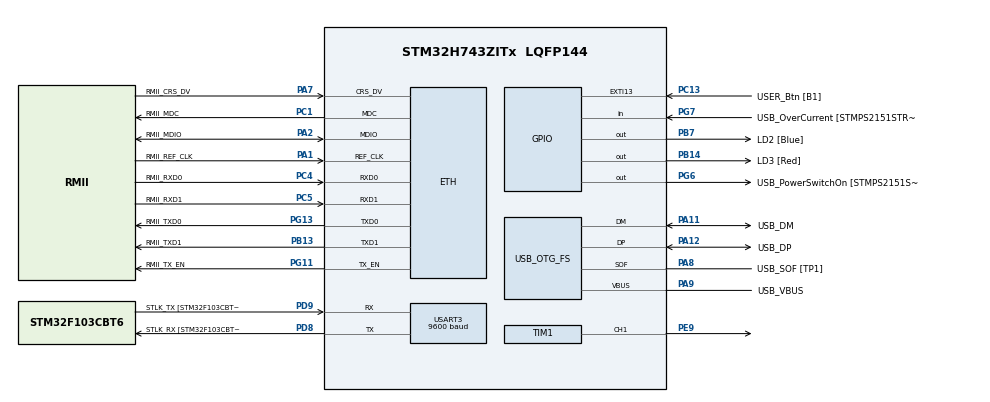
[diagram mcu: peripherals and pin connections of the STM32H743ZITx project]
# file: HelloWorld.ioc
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ETH.MediaInterface=HAL_ETH_RMII_MODE
Mcu.Family=STM32H7
Mcu.Name=STM32H743ZITx
Mcu.Package=LQFP144
NVIC.PriorityGroup=NVIC_PRIORITYGROUP_4
NVIC.USART3_IRQn=true\:0\:0\:false\:false\:true\:true\:true
PA1.GPIO_Label=RMII_REF_CLK
PA1.Mode=RMII
PA1.Signal=ETH_REF_CLK
PA10.GPIO_Label=USB_ID
PA10.Signal=USB_OTG_FS_ID
PA11.GPIO_Label=USB_DM
PA11.Mode=Device_Only
PA11.Signal=USB_OTG_FS_DM
PA12.GPIO_Label=USB_DP
PA12.Mode=Device_Only
PA12.Signal=USB_OTG_FS_DP
PA13\ (JTMS/SWDIO).Mode=Serial_Wire
PA13\ (JTMS/SWDIO).Signal=DEBUG_JTMS-SWDIO
PA14\ (JTCK/SWCLK).Mode=Serial_Wire
PA14\ (JTCK/SWCLK).Signal=DEBUG_JTCK-SWCLK
PA2.GPIO_Label=RMII_MDIO
PA2.Mode=RMII
PA2.Signal=ETH_MDIO
PA7.GPIO_Label=RMII_CRS_DV
PA7.Mode=RMII
PA7.Signal=ETH_CRS_DV
PA8.GPIO_Label=USB_SOF [TP1]
PA8.Mode=Activate_SOF_FS
PA8.Signal=USB_OTG_FS_SOF
PA9.GPIO_Label=USB_VBUS
PA9.Mode=Activate_VBUS
PA9.Signal=USB_OTG_FS_VBUS
PB13.GPIO_Label=RMII_TXD1
PB13.Mode=RMII
PB13.Signal=ETH_TXD1
PB14.GPIO_Label=LD3 [Red]
PB14.Signal=GPIO_Output
PB7.GPIO_Label=LD2 [Blue]
PB7.Signal=GPIO_Output
PC1.GPIO_Label=RMII_MDC
PC1.Mode=RMII
PC1.Signal=ETH_MDC
PC13.GPIO_Label=USER_Btn [B1]
PC13.Signal=GPXTI13
PC14-OSC32_IN\ (OSC32_IN).Mode=LSE-External-Oscillator
PC14-OSC32_IN\ (OSC32_IN).Signal=RCC_OSC32_IN
PC15-OSC32_OUT\ (OSC32_OUT).Mode=LSE-External-Oscillator
PC15-OSC32_OUT\ (OSC32_OUT).Signal=RCC_OSC32_OUT
PC4.GPIO_Label=RMII_RXD0
PC4.Mode=RMII
PC4.Signal=ETH_RXD0
PC5.GPIO_Label=RMII_RXD1
PC5.Mode=RMII
PC5.Signal=ETH_RXD1
PD8.GPIO_Label=STLK_RX [STM32F103CBT6_PA3]
PD8.Mode=Asynchronous
PD8.Signal=USART3_TX
PD9.GPIO_Label=STLK_TX [STM32F103CBT6_PA2]
PD9.Mode=Asynchronous
PD9.Signal=USART3_RX
PE9.Signal=S_TIM1_CH1
PG11.GPIO_Label=RMII_TX_EN
PG11.Mode=RMII
PG11.Signal=ETH_TX_EN
PG13.GPIO_Label=RMII_TXD0
PG13.Mode=RMII
PG13.Signal=ETH_TXD0
PG6.GPIO_Label=USB_PowerSwitchOn [STMPS2151STR_EN]
PG6.Signal=GPIO_Output
PG7.GPIO_Label=USB_OverCurrent [STMPS2151STR_FAULT]
PG7.Signal=GPIO_Input
PH0-OSC_IN\ (PH0).GPIO_Label=MCO
PH0-OSC_IN\ (PH0).Mode=HSE-External-Clock-Source
PH0-OSC_IN\ (PH0).Signal=RCC_OSC_IN
PH1-OSC_OUT\ (PH1).Signal=RCC_OSC_OUT
ProjectManager.HeapSize=0x200
ProjectManager.StackSize=0x400
ProjectManager.TargetToolchain=STM32CubeIDE
RCC.48MHZClocksFreq_Value=24000000
RCC.ADCFreq_Value=16125000
RCC.AHBFreq_Value=216000000
RCC.APB1CLKDivider=RCC_HCLK_DIV4
RCC.APB1Freq_Value=96000000
RCC.APB1TimFreq_Value=108000000
RCC.APB2CLKDivider=RCC_HCLK_DIV2
RCC.APB2Freq_Value=96000000
RCC.APB2TimFreq_Value=216000000
RCC.APB3Freq_Value=96000000
RCC.APB4Freq_Value=96000000
RCC.CortexFreq_Value=96000000
RCC.DIVM1=1
RCC.DIVN1=24
RCC.DIVQ1=4
RCC.HCLKFreq_Value=96000000
RCC.HSE_VALUE=8000000
RCC.HSI_VALUE=64000000
RCC.PLLM=25
RCC.PLLMUL=RCC_PLL_MUL9
RCC.PLLN=432
RCC.PLLQ=9
RCC.PRESCALERUSB=RCC_USBCLKSOURCE_PLL_DIV1_5
RCC.PWR_Regulator_Voltage_Scale=PWR_REGULATOR_VOLTAGE_SCALE1
RCC.SYSCLKFreq_VALUE=96000000
RCC.SYSCLKSource=RCC_SYSCLKSOURCE_PLLCLK
RCC.SYSCLKSourceVirtual=RCC_SYSCLKSOURCE_PLLCLK
RCC.USBFreq_Value=48000000
RCC.VCOOutputFreq_Value=432000000
SH.S_TIM1_CH1.0=TIM1_CH1,PWM Generation1 CH1
TIM1.Channel-PWM\ Generation1\ CH1=TIM_CHANNEL_1
USART3.BaudRate=9600
USART3.FIFOMode=FIFOMODE_ENABLE
USART3.TXFIFOThreshold=TXFIFO_THRESHOLD_1EIGHTHFULL
USART3.VirtualMode-Asynchronous=VM_ASYNC
USB_OTG_FS.VirtualMode=Device_Only
VP_TIM1_VS_ClockSourceINT.Mode=Internal
board=NUCLEO-H743ZI

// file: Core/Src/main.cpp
/* USER CODE BEGIN Header */
/**
  ******************************************************************************
  * @file           : main.c
  * @brief          : Main program body
  ******************************************************************************
  * @attention
  *
  * <h2><center>&copy; Copyright (c) 2020 STMicroelectronics.
  * All rights reserved.</center></h2>
  *
  * This software component is licensed by ST under BSD 3-Clause license,
  * the "License"; You may not use this file except in compliance with the
  * License. You may obtain a copy of the License at:
  *                        opensource.org/licenses/BSD-3-Clause
  *
  ******************************************************************************
  */
/* USER CODE END Header */

#include "main.h"
#include "string.h"

/* USER CODE BEGIN Includes */
#include "applicationManager.h"
/* USER CODE END Includes */

#if defined ( __ICCARM__ ) /*!< IAR Compiler */

#pragma location=0x30040000
ETH_DMADescTypeDef  DMARxDscrTab[ETH_RX_DESC_CNT]; /* Ethernet Rx DMA Descriptors */
#pragma location=0x30040060
ETH_DMADescTypeDef  DMATxDscrTab[ETH_TX_DESC_CNT]; /* Ethernet Tx DMA Descriptors */
#pragma location=0x30040200
uint8_t Rx_Buff[ETH_RX_DESC_CNT][ETH_MAX_PACKET_SIZE]; /* Ethernet Receive Buffers */

#elif defined ( __CC_ARM )  /* MDK ARM Compiler */

__attribute__((at(0x30040000))) ETH_DMADescTypeDef  DMARxDscrTab[ETH_RX_DESC_CNT]; /* Ethernet Rx DMA Descriptors */
__attribute__((at(0x30040060))) ETH_DMADescTypeDef  DMATxDscrTab[ETH_TX_DESC_CNT]; /* Ethernet Tx DMA Descriptors */
__attribute__((at(0x30040200))) uint8_t Rx_Buff[ETH_RX_DESC_CNT][ETH_MAX_PACKET_SIZE]; /* Ethernet Receive Buffer */

#elif defined ( __GNUC__ ) /* GNU Compiler */

ETH_DMADescTypeDef DMARxDscrTab[ETH_RX_DESC_CNT] __attribute__((section(".RxDecripSection"))); /* Ethernet Rx DMA Descriptors */
ETH_DMADescTypeDef DMATxDscrTab[ETH_TX_DESC_CNT] __attribute__((section(".TxDecripSection")));   /* Ethernet Tx DMA Descriptors */
uint8_t Rx_Buff[ETH_RX_DESC_CNT][ETH_MAX_PACKET_SIZE] __attribute__((section(".RxArraySection"))); /* Ethernet Receive Buffers */

#endif

ETH_TxPacketConfig TxConfig;

ETH_HandleTypeDef heth;

TIM_HandleTypeDef htim1;

UART_HandleTypeDef huart3;

PCD_HandleTypeDef hpcd_USB_OTG_FS;

/* USER CODE BEGIN PV */
ApplicationManager appMgr;
/* USER CODE END PV */

void SystemClock_Config(void);
static void MX_GPIO_Init(void);
static void MX_ETH_Init(void);
static void MX_USART3_UART_Init(void);
static void MX_USB_OTG_FS_PCD_Init(void);
static void MX_TIM1_Init(void);

int main(void)
{

  /* MCU Configuration--------------------------------------------------------*/

  /* Reset of all peripherals, Initializes the Flash interface and the Systick. */
  HAL_Init();

  /* Configure the system clock */
  SystemClock_Config();

  /* Initialize all configured peripherals */
  MX_GPIO_Init();
  MX_ETH_Init();
  MX_USART3_UART_Init();
  MX_USB_OTG_FS_PCD_Init();
  MX_TIM1_Init();
  /* USER CODE BEGIN 2 */
  appMgr.init(&huart3);
  /* USER CODE END 2 */

  /* Infinite loop */
  while (1)
  {
	  appMgr.executeMainFunction();
  }
}

void SystemClock_Config(void)
{
  RCC_OscInitTypeDef RCC_OscInitStruct = {0};
  RCC_ClkInitTypeDef RCC_ClkInitStruct = {0};
  RCC_PeriphCLKInitTypeDef PeriphClkInitStruct = {0};

  /** Supply configuration update enable
  */
  HAL_PWREx_ConfigSupply(PWR_LDO_SUPPLY);
  /** Configure the main internal regulator output voltage
  */
  __HAL_PWR_VOLTAGESCALING_CONFIG(PWR_REGULATOR_VOLTAGE_SCALE1);

  while(!__HAL_PWR_GET_FLAG(PWR_FLAG_VOSRDY)) {}
  /** Initializes the CPU, AHB and APB busses clocks
  */
  RCC_OscInitStruct.OscillatorType = RCC_OSCILLATORTYPE_HSE;
  RCC_OscInitStruct.HSEState = RCC_HSE_BYPASS;
  RCC_OscInitStruct.PLL.PLLState = RCC_PLL_ON;
  RCC_OscInitStruct.PLL.PLLSource = RCC_PLLSOURCE_HSE;
  RCC_OscInitStruct.PLL.PLLM = 1;
  RCC_OscInitStruct.PLL.PLLN = 24;
  RCC_OscInitStruct.PLL.PLLP = 2;
  RCC_OscInitStruct.PLL.PLLQ = 4;
  RCC_OscInitStruct.PLL.PLLR = 2;
  RCC_OscInitStruct.PLL.PLLRGE = RCC_PLL1VCIRANGE_3;
  RCC_OscInitStruct.PLL.PLLVCOSEL = RCC_PLL1VCOWIDE;
  RCC_OscInitStruct.PLL.PLLFRACN = 0;
  if (HAL_RCC_OscConfig(&RCC_OscInitStruct) != HAL_OK)
  {
    Error_Handler();
  }
  /** Initializes the CPU, AHB and APB busses clocks
  */
  RCC_ClkInitStruct.ClockType = RCC_CLOCKTYPE_HCLK|RCC_CLOCKTYPE_SYSCLK
                              |RCC_CLOCKTYPE_PCLK1|RCC_CLOCKTYPE_PCLK2
                              |RCC_CLOCKTYPE_D3PCLK1|RCC_CLOCKTYPE_D1PCLK1;
  RCC_ClkInitStruct.SYSCLKSource = RCC_SYSCLKSOURCE_PLLCLK;
  RCC_ClkInitStruct.SYSCLKDivider = RCC_SYSCLK_DIV1;
  RCC_ClkInitStruct.AHBCLKDivider = RCC_HCLK_DIV1;
  RCC_ClkInitStruct.APB3CLKDivider = RCC_APB3_DIV1;
  RCC_ClkInitStruct.APB1CLKDivider = RCC_APB1_DIV1;
  RCC_ClkInitStruct.APB2CLKDivider = RCC_APB2_DIV1;
  RCC_ClkInitStruct.APB4CLKDivider = RCC_APB4_DIV1;

  if (HAL_RCC_ClockConfig(&RCC_ClkInitStruct, FLASH_LATENCY_1) != HAL_OK)
  {
    Error_Handler();
  }
  PeriphClkInitStruct.PeriphClockSelection = RCC_PERIPHCLK_USART3|RCC_PERIPHCLK_USB;
  PeriphClkInitStruct.Usart234578ClockSelection = RCC_USART234578CLKSOURCE_D2PCLK1;
  PeriphClkInitStruct.UsbClockSelection = RCC_USBCLKSOURCE_PLL;
  if (HAL_RCCEx_PeriphCLKConfig(&PeriphClkInitStruct) != HAL_OK)
  {
    Error_Handler();
  }
  /** Enable USB Voltage detector
  */
  HAL_PWREx_EnableUSBVoltageDetector();
}

static void MX_ETH_Init(void)
{

  heth.Instance = ETH;
  heth.Init.MACAddr[0] =   0x00;
  heth.Init.MACAddr[1] =   0x80;
  heth.Init.MACAddr[2] =   0xE1;
  heth.Init.MACAddr[3] =   0x00;
  heth.Init.MACAddr[4] =   0x00;
  heth.Init.MACAddr[5] =   0x00;
  heth.Init.MediaInterface = HAL_ETH_RMII_MODE;
  heth.Init.TxDesc = DMATxDscrTab;
  heth.Init.RxDesc = DMARxDscrTab;
  heth.Init.RxBuffLen = 1524;

  if (HAL_ETH_Init(&heth) != HAL_OK)
  {
    Error_Handler();
  }

  memset(&TxConfig, 0 , sizeof(ETH_TxPacketConfig));
  TxConfig.Attributes = ETH_TX_PACKETS_FEATURES_CSUM | ETH_TX_PACKETS_FEATURES_CRCPAD;
  TxConfig.ChecksumCtrl = ETH_CHECKSUM_IPHDR_PAYLOAD_INSERT_PHDR_CALC;
  TxConfig.CRCPadCtrl = ETH_CRC_PAD_INSERT;

}

static void MX_TIM1_Init(void)
{

  TIM_ClockConfigTypeDef sClockSourceConfig = {0};
  TIM_MasterConfigTypeDef sMasterConfig = {0};
  TIM_OC_InitTypeDef sConfigOC = {0};
  TIM_BreakDeadTimeConfigTypeDef sBreakDeadTimeConfig = {0};

  htim1.Instance = TIM1;
  htim1.Init.Prescaler = 0;
  htim1.Init.CounterMode = TIM_COUNTERMODE_UP;
  htim1.Init.Period = 0;
  htim1.Init.ClockDivision = TIM_CLOCKDIVISION_DIV1;
  htim1.Init.RepetitionCounter = 0;
  htim1.Init.AutoReloadPreload = TIM_AUTORELOAD_PRELOAD_DISABLE;
  if (HAL_TIM_Base_Init(&htim1) != HAL_OK)
  {
    Error_Handler();
  }
  sClockSourceConfig.ClockSource = TIM_CLOCKSOURCE_INTERNAL;
  if (HAL_TIM_ConfigClockSource(&htim1, &sClockSourceConfig) != HAL_OK)
  {
    Error_Handler();
  }
  if (HAL_TIM_PWM_Init(&htim1) != HAL_OK)
  {
    Error_Handler();
  }
  sMasterConfig.MasterOutputTrigger = TIM_TRGO_RESET;
  sMasterConfig.MasterOutputTrigger2 = TIM_TRGO2_RESET;
  sMasterConfig.MasterSlaveMode = TIM_MASTERSLAVEMODE_DISABLE;
  if (HAL_TIMEx_MasterConfigSynchronization(&htim1, &sMasterConfig) != HAL_OK)
  {
    Error_Handler();
  }
  sConfigOC.OCMode = TIM_OCMODE_PWM1;
  sConfigOC.Pulse = 0;
  sConfigOC.OCPolarity = TIM_OCPOLARITY_HIGH;
  sConfigOC.OCNPolarity = TIM_OCNPOLARITY_HIGH;
  sConfigOC.OCFastMode = TIM_OCFAST_DISABLE;
  sConfigOC.OCIdleState = TIM_OCIDLESTATE_RESET;
  sConfigOC.OCNIdleState = TIM_OCNIDLESTATE_RESET;
  if (HAL_TIM_PWM_ConfigChannel(&htim1, &sConfigOC, TIM_CHANNEL_1) != HAL_OK)
  {
    Error_Handler();
  }
  sBreakDeadTimeConfig.OffStateRunMode = TIM_OSSR_DISABLE;
  sBreakDeadTimeConfig.OffStateIDLEMode = TIM_OSSI_DISABLE;
  sBreakDeadTimeConfig.LockLevel = TIM_LOCKLEVEL_OFF;
  sBreakDeadTimeConfig.DeadTime = 0;
  sBreakDeadTimeConfig.BreakState = TIM_BREAK_DISABLE;
  sBreakDeadTimeConfig.BreakPolarity = TIM_BREAKPOLARITY_HIGH;
  sBreakDeadTimeConfig.BreakFilter = 0;
  sBreakDeadTimeConfig.Break2State = TIM_BREAK2_DISABLE;
  sBreakDeadTimeConfig.Break2Polarity = TIM_BREAK2POLARITY_HIGH;
  sBreakDeadTimeConfig.Break2Filter = 0;
  sBreakDeadTimeConfig.AutomaticOutput = TIM_AUTOMATICOUTPUT_DISABLE;
  if (HAL_TIMEx_ConfigBreakDeadTime(&htim1, &sBreakDeadTimeConfig) != HAL_OK)
  {
    Error_Handler();
  }
  HAL_TIM_MspPostInit(&htim1);

}

static void MX_USART3_UART_Init(void)
{

  huart3.Instance = USART3;
  huart3.Init.BaudRate = 115200;
  huart3.Init.WordLength = UART_WORDLENGTH_8B;
  huart3.Init.StopBits = UART_STOPBITS_1;
  huart3.Init.Parity = UART_PARITY_NONE;
  huart3.Init.Mode = UART_MODE_TX_RX;
  huart3.Init.HwFlowCtl = UART_HWCONTROL_NONE;
  huart3.Init.OverSampling = UART_OVERSAMPLING_16;
  huart3.Init.OneBitSampling = UART_ONE_BIT_SAMPLE_DISABLE;
  huart3.Init.ClockPrescaler = UART_PRESCALER_DIV1;
  huart3.AdvancedInit.AdvFeatureInit = UART_ADVFEATURE_NO_INIT;
  if (HAL_UART_Init(&huart3) != HAL_OK)
  {
    Error_Handler();
  }
  if (HAL_UARTEx_SetTxFifoThreshold(&huart3, UART_TXFIFO_THRESHOLD_1_4) != HAL_OK)
  {
    Error_Handler();
  }
  if (HAL_UARTEx_SetRxFifoThreshold(&huart3, UART_TXFIFO_THRESHOLD_1_4) != HAL_OK)
  {
    Error_Handler();
  }
  if (HAL_UARTEx_DisableFifoMode(&huart3) != HAL_OK)
  {
    Error_Handler();
  }

}

static void MX_USB_OTG_FS_PCD_Init(void)
{

  hpcd_USB_OTG_FS.Instance = USB_OTG_FS;
  hpcd_USB_OTG_FS.Init.dev_endpoints = 9;
  hpcd_USB_OTG_FS.Init.speed = PCD_SPEED_FULL;
  hpcd_USB_OTG_FS.Init.dma_enable = DISABLE;
  hpcd_USB_OTG_FS.Init.phy_itface = PCD_PHY_EMBEDDED;
  hpcd_USB_OTG_FS.Init.Sof_enable = ENABLE;
  hpcd_USB_OTG_FS.Init.low_power_enable = DISABLE;
  hpcd_USB_OTG_FS.Init.lpm_enable = DISABLE;
  hpcd_USB_OTG_FS.Init.battery_charging_enable = ENABLE;
  hpcd_USB_OTG_FS.Init.vbus_sensing_enable = ENABLE;
  hpcd_USB_OTG_FS.Init.use_dedicated_ep1 = DISABLE;
  if (HAL_PCD_Init(&hpcd_USB_OTG_FS) != HAL_OK)
  {
    Error_Handler();
  }

}

static void MX_GPIO_Init(void)
{
  GPIO_InitTypeDef GPIO_InitStruct = {0};

  /* GPIO Ports Clock Enable */
  __HAL_RCC_GPIOC_CLK_ENABLE();
  __HAL_RCC_GPIOH_CLK_ENABLE();
  __HAL_RCC_GPIOA_CLK_ENABLE();
  __HAL_RCC_GPIOE_CLK_ENABLE();
  __HAL_RCC_GPIOB_CLK_ENABLE();
  __HAL_RCC_GPIOD_CLK_ENABLE();
  __HAL_RCC_GPIOG_CLK_ENABLE();

  /*Configure GPIO pin Output Level */
  HAL_GPIO_WritePin(GPIOB, LD3_Pin|LD2_Pin, GPIO_PIN_RESET);

  /*Configure GPIO pin Output Level */
  HAL_GPIO_WritePin(USB_PowerSwitchOn_GPIO_Port, USB_PowerSwitchOn_Pin, GPIO_PIN_RESET);

  /*Configure GPIO pin : USER_Btn_Pin */
  GPIO_InitStruct.Pin = USER_Btn_Pin;
  GPIO_InitStruct.Mode = GPIO_MODE_IT_RISING;
  GPIO_InitStruct.Pull = GPIO_NOPULL;
  HAL_GPIO_Init(USER_Btn_GPIO_Port, &GPIO_InitStruct);

  /*Configure GPIO pins : LD3_Pin LD2_Pin */
  GPIO_InitStruct.Pin = LD3_Pin|LD2_Pin;
  GPIO_InitStruct.Mode = GPIO_MODE_OUTPUT_PP;
  GPIO_InitStruct.Pull = GPIO_NOPULL;
  GPIO_InitStruct.Speed = GPIO_SPEED_FREQ_LOW;
  HAL_GPIO_Init(GPIOB, &GPIO_InitStruct);

  /*Configure GPIO pin : USB_PowerSwitchOn_Pin */
  GPIO_InitStruct.Pin = USB_PowerSwitchOn_Pin;
  GPIO_InitStruct.Mode = GPIO_MODE_OUTPUT_PP;
  GPIO_InitStruct.Pull = GPIO_NOPULL;
  GPIO_InitStruct.Speed = GPIO_SPEED_FREQ_LOW;
  HAL_GPIO_Init(USB_PowerSwitchOn_GPIO_Port, &GPIO_InitStruct);

  /*Configure GPIO pin : USB_OverCurrent_Pin */
  GPIO_InitStruct.Pin = USB_OverCurrent_Pin;
  GPIO_InitStruct.Mode = GPIO_MODE_INPUT;
  GPIO_InitStruct.Pull = GPIO_NOPULL;
  HAL_GPIO_Init(USB_OverCurrent_GPIO_Port, &GPIO_InitStruct);

}

void Error_Handler(void)
{
}

/************************ (C) COPYRIGHT STMicroelectronics *****END OF FILE****/
